# APM32F411 register map
Vendor: Geehy; File version: 2024.11.05
CPU: CM4 r1p0, little endian, 3 interrupt priority bits
Registers are 32-bit, read-write, reset 0x0 unless marked. A register's access mark holds for its fields unless they carry their own. Offsets are from the block's base; [hi:lo] are bit positions; lines under a group give offsets from that group; {n}, {i} and the like mark numbered series.

## ADC1 — Analog-to-digital converter
Base 0x40012000
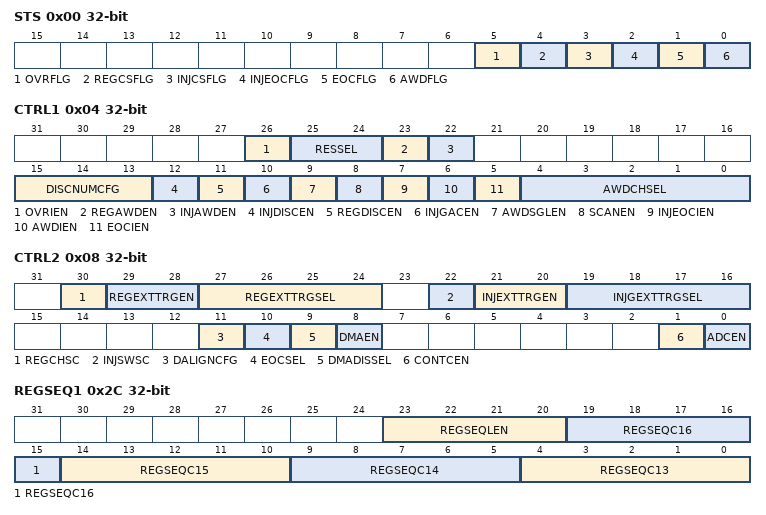
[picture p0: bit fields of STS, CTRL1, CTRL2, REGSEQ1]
0x00 STS — Reports various ADC status flags such as analog watchdog event, end of conversion for both regular and injected channels, start flags, and overrun detection.
  [5] OVRFLG — Indicates an overrun event occurred (new data overwritten before previous data was read).
  [4] REGCSFLG — Indicates whether a regular channel conversion has started.
  [3] INJCSFLG — Indicates whether an injected channel conversion has started.
  [2] INJEOCFLG — Indicates whether an injected channel conversion has completed.
  [1] EOCFLG — Indicates whether a regular channel conversion has completed.
  [0] AWDFLG — Indicates whether an analog watchdog event has occurred (voltage out of the configured thresholds).
0x04 CTRL1 — ADC control register 1. Configures the analog watchdog channel selection, various interrupts, scan mode, discontinuous mode, resolution, and other important ADC operating parameters.
  [26] OVRIEN — Enables or disables the interrupt when an overrun occurs. An overrun occurs if new data overwrites old data in the data register before it is read.
    0=DISABLE (Overrun interrupt is disabled.); 1=ENABLE (Overrun interrupt is enabled.)
  [25:24] RESSEL — Configures the ADC resolution. 00 = 12-bit, 01 = 10-bit, 10 = 8-bit, 11 = 6-bit.
    0=RES12 (ADC operates at 12-bit resolution.); 1=RES10 (ADC operates at 10-bit resolution.); 2=RES8 (ADC operates at 8-bit resolution.); 3=RES6 (ADC operates at 6-bit resolution.)
  [23] REGAWDEN — When set, the analog watchdog function is applied to the regular channels.
    0=DISABLE (Analog watchdog does not monitor regular channels.); 1=ENABLE (Analog watchdog monitors regular channels.)
  [22] INJAWDEN — When set, the analog watchdog function is applied to the injected channels as well.
    0=DISABLE (Analog watchdog does not monitor injected channels.); 1=ENABLE (Analog watchdog monitors injected channels.)
  [15:13] DISCNUMCFG — Specifies the number of channels in each discontinuous group for regular channel conversions. 000 = 1 channel, 001 = 2 channels, ... 111 = 8 channels.
    0=ONE (Each sub-group conversion has 1 channel.); 1=TWO (Each sub-group conversion has 2 channels.); 2=THREE (Each sub-group conversion has 3 channels.); 3=FOUR (Each sub-group conversion has 4 channels.); 4=FIVE (Each sub-group conversion has 5 channels.); 5=SIX (Each sub-group conversion has 6 channels.); 6=SEVEN (Each sub-group conversion has 7 channels.); 7=EIGHT (Each sub-group conversion has 8 channels.)
  [12] INJDISCEN — Enables or disables discontinuous mode on the injected channel sequence.
    0=DISABLE (Injected channels operate in normal (full) injected scan mode.); 1=ENABLE (Injected channels are converted in smaller sub-groups triggered each time.)
  [11] REGDISCEN — Enables or disables discontinuous mode on the regular channel sequence.
    0=DISABLE (Regular channels operate in normal (continuous or single) scan mode.); 1=ENABLE (Regular channels are converted in smaller sub-groups triggered each time.)
  [10] INJGACEN — When set, the ADC automatically starts the injected group conversion after the regular group conversion completes.
    0=DISABLE (Injected group conversions are triggered manually or by an external source.); 1=ENABLE (Automatic injected conversion starts after a regular conversion sequence completes.)
  [9] AWDSGLEN — When set, the analog watchdog monitors only a single channel (selected by AWDCHSEL) in scan mode. Otherwise, it monitors all channels in the scan.
    0=ALLCHANNELS (Analog watchdog monitors all channels in scan mode.); 1=SINGLECHANNEL (Analog watchdog monitors only the channel defined by AWDCHSEL.)
  [8] SCANEN — Enables or disables scan mode for regular or injected channel sequences.
    0=DISABLE (Single channel or single conversion mode operation.); 1=ENABLE (Scans through multiple channels in a sequence.)
  [7] INJEOCIEN — Enables or disables the interrupt when an injected channel conversion completes.
    0=DISABLE (Injected EOC interrupt is disabled.); 1=ENABLE (Injected EOC interrupt is enabled.)
  [6] AWDIEN — Enables or disables the interrupt when the analog watchdog detects that the input signal has crossed the threshold boundaries.
    0=DISABLE (Watchdog interrupt is disabled.); 1=ENABLE (Watchdog interrupt is enabled.)
  [5] EOCIEN — Enables or disables the interrupt when a regular channel conversion is complete.
    0=DISABLE (EOC interrupt is disabled.); 1=ENABLE (EOC interrupt is enabled.)
  [4:0] AWDCHSEL — Selects the ADC channel to be monitored by the analog watchdog. Valid values range from 0 to 16. Other values are reserved.
    {v}=CH{v} (Monitor ADC analog input channel {v}.) (v=0..16)
0x08 CTRL2 — ADC control register 2. Configures ADC enable, single/continuous operation, DMA behavior, data alignment, external triggers for regular and injected conversions, and software start triggers.
  [30] REGCHSC — Software start for regular channels. Writing 1 triggers regular channel conversions if external trigger is disabled or set appropriately.
    0=NO_START (No software trigger for regular channels.); 1=START (Start regular channel conversion via software.)
  [29:28] REGEXTTRGEN — Enables or disables the detection edge for the external trigger on regular channels. 00 = disabled, 01 = rising edge, 10 = falling edge, 11 = both edges.
    0=DISABLED (No external trigger detection for regular channels.); 1=RISING (Trigger on rising edge of selected external signal.); 2=FALLING (Trigger on falling edge of selected external signal.); 3=BOTH (Trigger on both rising and falling edges.)
  [27:24] REGEXTTRGSEL — Selects the external event to start the regular channel conversion. Refer to Table 129 in the reference manual for possible trigger sources.
    0=TMR1_CC1 (Timer 1 CC1 event); 1=TMR1_CC2 (Timer 1 CC2 event); 2=TMR1_CC3 (Timer 1 CC3 event); 3=TMR2_CC2 (Timer 2 CC2 event); 4=TMR2_CC3 (Timer 2 CC3 event); 5=TMR2_CC4 (Timer 2 CC4 event); 6=TMR2_TRGO (Timer 2 TRGO event); 7=TMR3_CC1 (Timer 3 CC1 event); 8=TMR3_TRGO (Timer 3 TRGO event); 9=TMR4_CC4 (Timer 4 CC4 event); 10=TMR5_CC1 (Timer 5 CC1 event); 11=TMR5_CC2 (Timer 5 CC2 event); 12=TMR5_CC3 (Timer 5 CC3 event); 13=TMR8_CC1 (Timer 8 CC1 event); 14=TMR8_TRGO (Timer 8 TRGO event); 15=EINT_LINE11 (External pin (EXTI line 11))
  [22] INJSWSC — Software start for injected channels. Writing 1 triggers injected channel conversions if external trigger is disabled or set appropriately.
    0=NO_START (No software trigger for injected channels.); 1=START (Start injected channels conversion via software.)
  [21:20] INJEXTTRGEN — Enables or disables the detection edge for the external trigger on injected channels.
    0=DISABLED (No external trigger detection for injected channels.); 1=RISING (Trigger on rising edge of selected external signal.); 2=FALLING (Trigger on falling edge of selected external signal.); 3=BOTH (Trigger on both rising and falling edges.)
  [19:16] INJGEXTTRGSEL — Selects the external event to start the injected group conversion. Refer to Table 130 in the reference manual for possible trigger sources.
    0=TMR1_CC4 (Timer 1 CC4 event); 1=TMR1_TRGO (Timer 1 TRGO event); 2=TMR2_CC1 (Timer 2 CC1 event); 3=TMR2_TRGO (Timer 2 TRGO event); 4=TMR3_CC2 (Timer 3 CC2 event); 5=TMR3_CC4 (Timer 3 CC4 event); 6=TMR4_CC1 (Timer 4 CC1 event); 7=TMR4_CC2 (Timer 4 CC2 event); 8=TMR4_CC3 (Timer 4 CC3 event); 9=TMR4_TRGO (Timer 4 TRGO event); 10=TMR5_CC4 (Timer 5 CC4 event); 11=TMR5_TRGO (Timer 5 TRGO event); 12=TMR8_CC2 (Timer 8 CC2 event); 13=TMR8_CC3 (Timer 8 CC3 event); 14=TMR8_CC4 (Timer 8 CC4 event); 15=EINT_LINE15 (External pin (EXTI line 15))
  [11] DALIGNCFG — Selects the alignment of ADC conversion data.
    0=RIGHT (Converted data is right-aligned in the ADC data register.); 1=LEFT (Converted data is left-aligned in the ADC data register.)
  [10] EOCSEL — Selects when the EOC flag is set.
    0=SEQ (EOC flag is set once per entire conversion sequence.); 1=EACH (EOC flag is set after each channel conversion within the sequence.)
  [9] DMADISSEL — Specifies how DMA requests are generated when DMA is enabled (in single ADC mode).
    0=ONESHOT (No further DMA requests after the last completed transmission.); 1=CONT (DMA requests continue whenever data conversion occurs.)
  [8] DMAEN — Enables or disables DMA requests when regular conversions complete (in single ADC mode).
    0=DISABLE (No DMA requests are generated after conversion completes.); 1=ENABLE (DMA requests are generated to transfer conversion results.)
  [1] CONTCEN — Selects single or continuous conversion mode. 0 = single conversion, 1 = continuous conversion.
    0=SINGLE (The ADC performs only one conversion per trigger.); 1=CONTINUOUS (The ADC performs back-to-back conversions after a start.)
  [0] ADCEN — Enables or disables the ADC. 0 = ADC in power-down mode, 1 = ADC enabled.
    0=DISABLE (The ADC is powered down and no conversions occur.); 1=ENABLE (The ADC is enabled and ready for conversions.)
0x0C SMPTIM1 — Configures the sample times for ADC channels 0 to 9. Each channel is assigned a 3-bit field, indicating the number of ADC clock cycles used for sampling.
  [26:0] SMPCYCCFG1 — SMPCYCCFG1 covers multiple channels (channels 0..9, 3 bits each = 30 bits), but here it's only 27 bits in total. The chapter indicates 8 or 10 channels per register, etc. This is a summary of possible arrangement. SMPCYCCFG1 holds the sample time configurations (3 bits per channel) for multiple ADC channels. Each 3-bit field defines the number of cycles for sampling: 000 = 3 cycles, 001 = 15 cycles, 010 = 28 cycles, 011 = 56 cycles, 100 = 84 cycles, 101 = 112 cycles, 110 = 144 cycles, 111 = 480 cycles. Note: Only 27 bits are used here (9 channels x 3 bits).
0x10 SMPTIM2 — Configures the sample times for additional ADC channels (e.g. 10 to 17). Each channel is assigned a 3-bit field, indicating the number of ADC clock cycles used for sampling.
  [29:0] SMPCYCCFG2 — SMPCYCCFG2 covers more channels with 3 bits each. According to the chapter, 30 bits might be enough for 10 channels. SMPCYCCFG2 holds the sample time configurations (3 bits per channel) for additional ADC channels. Each 3-bit field defines the number of cycles for sampling: 000 = 3 cycles, 001 = 15 cycles, 010 = 28 cycles, 011 = 56 cycles, 100 = 84 cycles, 101 = 112 cycles, 110 = 144 cycles, 111 = 480 cycles. Note: 30 bits used here (10 channels x 3 bits).
{0x10+4i} INJDOF{i} (i=1..4) — Defines the offset value subtracted from the raw conversion result for injected channel {i}.
  [11:0] INJDOF{i} — Data offset for injected channel {i}. This 12-bit value is subtracted from the raw conversion result before it is stored.
0x24 AWDHT reset 0xFFF — Analog watchdog high-threshold register used to define the upper voltage threshold for monitoring analog input signals.
  [11:0] AWDHT — Specifies the high voltage threshold for the analog watchdog. When the ADC input signal exceeds this threshold, an analog watchdog event is triggered.
0x28 AWDLT — Analog watchdog low-threshold register used to define the lower voltage threshold for monitoring analog input signals.
  [11:0] AWDLT — Specifies the low voltage threshold for the analog watchdog. When the ADC input signal drops below this threshold, an analog watchdog event is triggered.
0x2C REGSEQ1 — Configures the 13ᵗʰ to 16ᵗʰ channels in the regular conversion sequence, as well as the total length of the regular sequence.
  [23:20] REGSEQLEN — Specifies the total number of conversions in the regular sequence.
    0=ONE (The regular sequence has 1 channel.); 1=TWO (The regular sequence has 2 channels.); 2=THREE (The regular sequence has 3 channels.); 3=FOUR (The regular sequence has 4 channels.); 4=FIVE (The regular sequence has 5 channels.); 5=SIX (The regular sequence has 6 channels.); 6=SEVEN (The regular sequence has 7 channels.); 7=EIGHT (The regular sequence has 8 channels.); 8=NINE (The regular sequence has 9 channels.); 9=TEN (The regular sequence has 10 channels.); 10=ELEVEN (The regular sequence has 11 channels.); 11=TWELVE (The regular sequence has 12 channels.); 12=THIRTEEN (The regular sequence has 13 channels.); 13=FOURTEEN (The regular sequence has 14 channels.); 14=FIFTEEN (The regular sequence has 15 channels.); 15=SIXTEEN (The regular sequence has 16 channels.)
  [19:15] REGSEQC16 — Channel number for the 16th conversion in the regular sequence. Valid range: 0-17.
  [14:10] REGSEQC15 — Channel number for the 15th conversion in the regular sequence. Valid range: 0-17.
  [9:5] REGSEQC14 — Channel number for the 14th conversion in the regular sequence. Valid range: 0-17.
  [4:0] REGSEQC13 — Channel number for the 13th conversion in the regular sequence. Valid range: 0-17 (external or internal ADC channels).
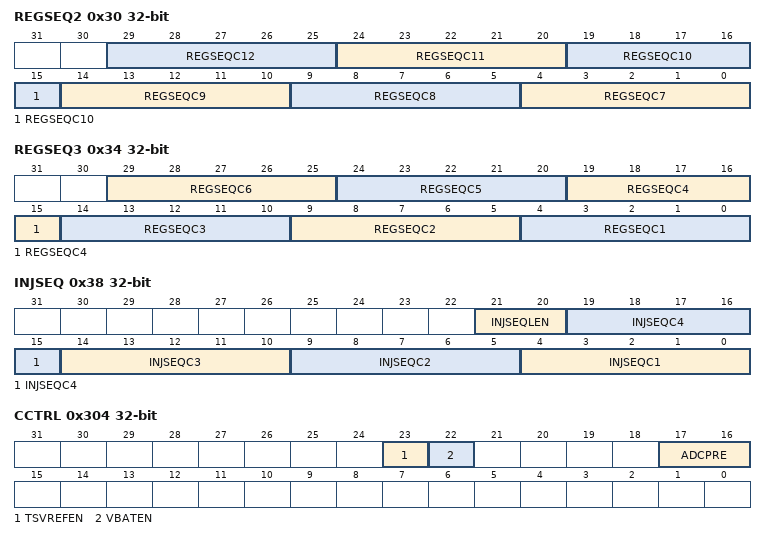
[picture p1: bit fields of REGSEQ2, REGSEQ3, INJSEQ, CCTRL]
0x30 REGSEQ2 — Configures the 7ᵗʰ to 12ᵗʰ channels in the regular conversion sequence.
  [5n-31:5n-35] REGSEQC{n} (n=7..12) — Channel number for the {n}th conversion in the regular sequence. Valid range: 0-17.
0x34 REGSEQ3 — Configures the 1ˢᵗ to 6ᵗʰ channels in the regular conversion sequence.
  [29:25] REGSEQC6 — Channel number for the 6th conversion in the regular sequence. Valid range: 0-17.
  [24:20] REGSEQC5 — Channel number for the 5th conversion in the regular sequence. Valid range: 0-17.
  [19:15] REGSEQC4 — Channel number for the 4th conversion in the regular sequence. Valid range: 0-17.
  [14:10] REGSEQC3 — Channel number for the 3rd conversion in the regular sequence. Valid range: 0-17.
  [9:5] REGSEQC2 — Channel number for the 2nd conversion in the regular sequence. Valid range: 0-17.
  [4:0] REGSEQC1 — Channel number for the 1st conversion in the regular sequence. Valid range: 0-17.
0x38 INJSEQ — Configures the injected channels sequence and the total number of injected conversions (sequence length).
  [21:20] INJSEQLEN — Specifies how many conversions are performed in the injected sequence.
    0=ONE (Sequence performs only 1 conversion: INJSEQ4); 1=TWO (Sequence performs INJSEQ3 → INJSEQ4); 2=THREE (Sequence performs INJSEQ2 → INJSEQ3 → INJSEQ4); 3=FOUR (Sequence performs INJSEQ1 → INJSEQ2 → INJSEQ3 → INJSEQ4)
  [19:15] INJSEQC4 — Channel number for the 4th conversion in the injected sequence. Valid range: 0-17 (external or internal ADC channels).
  [14:10] INJSEQC3 — Channel number for the 3rd conversion in the injected sequence. Valid range: 0-17 (external or internal ADC channels).
  [9:5] INJSEQC2 — Channel number for the 2nd conversion in the injected sequence. Valid range: 0-17 (external or internal ADC channels).
  [4:0] INJSEQC1 — Channel number for the 1st conversion in the injected sequence. Valid range: 0-17 (external or internal ADC channels).
{0x38+4i} INJDATA{i} ro (i=1..4) — Holds the converted data of the injected channel(s). Only the lower 16 bits are used to store the conversion result; the upper 16 bits are reserved.
  [15:0] INJDATA — Conversion result of the injected channel. Bits [15:0] hold the valid data, while the upper 16 bits are reserved.
0x4C REGDATA ro — Holds the conversion data of the regular channels. In single-ADC mode, only the lower 16 bits are used for the ADC data. In dual-ADC mode, the upper 16 bits store the conversion data of the second ADC.
  [15:0] REGDATA — Conversion result of the regular channel(s). In single-ADC mode, bits [15:0] hold the ADC data. In dual-ADC mode, bits [15:0] hold ADC1 data and bits [31:16] hold ADC2 data.
0x304 CCTRL — General-purpose control register for ADC. This register configures the ADC prescaler and enables monitoring of VBAT, temperature sensor, and the internal reference voltage.
  [23] TSVREFEN — Enable the on-chip temperature sensor and internal reference voltage for ADC measurement.
    0=DISABLE (Temperature sensor and VREFINT are disabled.); 1=ENABLE (Temperature sensor and VREFINT are enabled.)
  [22] VBATEN — Enable the VBAT channel for ADC measurement.
    0=DISABLE (VBAT measurement is disabled.); 1=ENABLE (VBAT measurement is enabled.)
  [17:16] ADCPRE — Selects the division factor from PCLK2 to generate the ADC clock. Valid configurations: 00 (PCLK2/2), 01 (PCLK2/4), 10 (PCLK2/6), 11 (PCLK2/8).
    0=DIV2 (Prescaler divides the PCLK2 by 2.); 1=DIV4 (Prescaler divides the PCLK2 by 4.); 2=DIV6 (Prescaler divides the PCLK2 by 6.); 3=DIV8 (Prescaler divides the PCLK2 by 8.)

## ADC2 — Analog-to-digital converter
Base 0x40012400
Registers as ADC1, without CCTRL; these are added or differ:
0x4C REGDATA ro — Holds the conversion data of the regular channels. In single-ADC mode, only the lower 16 bits are used for the ADC data. In dual-ADC mode, the upper 16 bits store the conversion data of the second ADC.
  [15:0] REGDATA — Conversion result of the regular channel(s). In single-ADC mode, bits [15:0] hold the ADC data. In dual-ADC mode, bits [15:0] hold ADC1 data and bits [31:16] hold ADC2 data.
